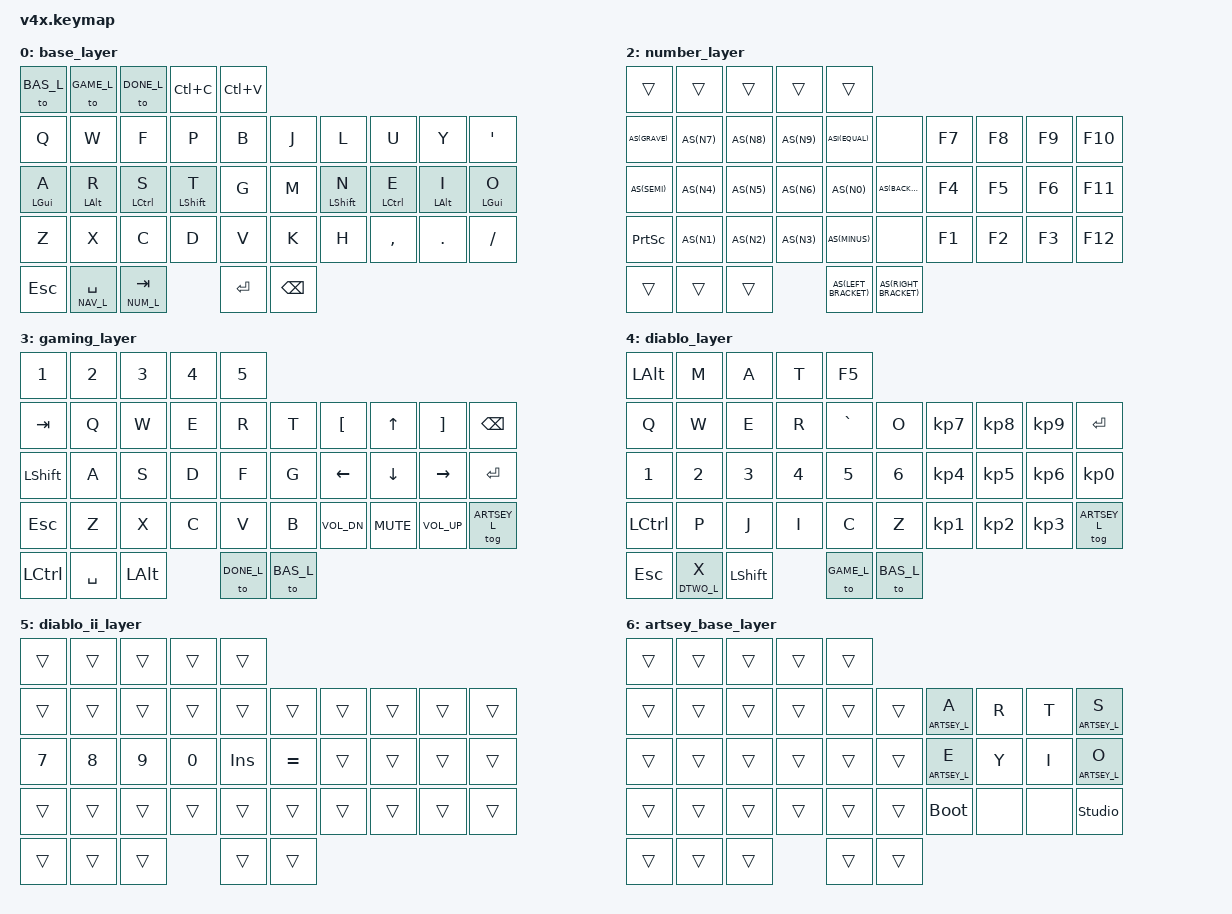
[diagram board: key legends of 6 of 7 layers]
/*
 * Copyright (c) 2024 Rooks
 * 
 * SPDX-License-Identifier: MIT
 */

#include <behaviors.dtsi>
#include <dt-bindings/zmk/keys.h>
#include <dt-bindings/zmk/bt.h>
#include <dt-bindings/zmk/outputs.h>

#define AS(keycode) &as LS(keycode) keycode     // Autoshift Macro
#define ASI(keycode) &as keycode LS(keycode)     // Autoshift Macro inverted
#define BAS_L 0
#define NAV_L 1
#define NUM_L 2
#define GAME_L 3
#define DONE_L 4
#define DTWO_L 5
#define ARTSEY_L 6

#define KEYS_L 5  6  7  8  9   15 16 17 18 19  25 26 27 28 29
#define KEYS_R 10 11 12 13 14  20 21 22 23 24  30 31 32 33 34

#define THUMBS 35 36 37 38 39

// Using layer taps on thumbs, having quick tap as well helps w/ repeating space/backspace
&lt { quick_tap_ms = <200>; };

#define BT(n) BT_SEL n

/ {
    behaviors {
        hml: hrm_left {
            compatible = "zmk,behavior-hold-tap";
            #binding-cells = <2>;
            flavor = "balanced";
            tapping-term-ms = <200>;
            quick-tap-ms = <150>;
            bindings = <&kp>, <&kp>;
            hold-trigger-key-positions = <KEYS_R THUMBS>;
            hold-trigger-on-release;
        };
        hmr: hrm_right {
            compatible = "zmk,behavior-hold-tap";
            #binding-cells = <2>;
            flavor = "balanced";
            tapping-term-ms = <200>;
            quick-tap-ms = <150>;
            bindings = <&kp>, <&kp>;
            hold-trigger-key-positions = <KEYS_L THUMBS>;
            hold-trigger-on-release;
        };
        as: auto_shift {
            compatible = "zmk,behavior-hold-tap";
            #binding-cells = <2>;
            tapping_term_ms = <200>;
            quick_tap_ms = <100>;
            flavor = "tap-preferred";
            bindings = <&kp>, <&kp>;
        };
    };

    keymap {
        compatible = "zmk,keymap";

        base_layer {
            bindings = <
                       &to BAS_L    &to GAME_L &to DONE_L &kp LC(C) &kp LC(V)
                &kp Q         &kp W         &kp F          &kp P           &kp B       &kp J      &kp L          &kp U          &kp Y         &kp QUOT
                &hml LGUI A   &hml LALT R   &hml LCTRL S   &hml LSHFT T    &kp G       &kp M      &hmr LSHFT N   &hmr LCTRL E   &hmr LALT I   &hmr LGUI O   
                &kp Z         &kp X         &kp C          &kp D           &kp V       &kp K      &kp H          &kp COMMA      &kp DOT       &kp FSLH
                &kp ESC        &lt NAV_L SPACE &lt NUM_L TAB        &kp RET    &kp BKSP
                >;
        };
        navigate_layer {
            bindings = <
                &trans &bt BT(0) &bt BT(1) &kp C_VOL_DN &kp C_VOL_UP
                &none &none &none &none &kp HOME     &kp PG_UP    &kp C_MUTE  &kp C_VOL_DN &kp C_VOL_UP &none
                &kp LEFT       &kp DOWN       &kp UP       &kp RIGHT       &out OUT_USB &out OUT_BLE &kp LSHFT &kp LCTRL    &kp LALT     &kp LGUI
                &none &none &none &none &kp END      &kp PG_DN    &caps_word &bt BT(0)    &bt BT(1)    &bt BT(2)
                                              &trans       &trans          &none &none &none
                >;
        };

        number_layer {
            bindings = <
                &trans &trans &trans &trans &trans
                AS(GRAVE) AS(N7) AS(N8) AS(N9) ASI(EQUAL) &none &kp F7 &kp F8 &kp F9 &kp F10
                AS(SEMI)  AS(N4) AS(N5) AS(N6) AS(N0)     AS(BACKSLASH) &kp F4 &kp F5 &kp F6 &kp F11
                &kp PSCRN AS(N1) AS(N2) AS(N3) AS(MINUS)  &none &kp F1 &kp F2 &kp F3 &kp F12
                    &trans &trans &trans AS(LEFT_BRACKET) AS(RIGHT_BRACKET)
                >;
        };

        gaming_layer {
            bindings = <
                &kp N1 &kp N2 &kp N3 &kp N4 &kp N5
                &kp TAB    &kp Q &kp W &kp E &kp R &kp T &kp LEFT_BRACKET &kp UP   &kp RIGHT_BRACKET &kp BACKSPACE
                &kp LSHIFT &kp A &kp S &kp D &kp F &kp G &kp LEFT         &kp DOWN &kp RIGHT         &kp RETURN
                &kp ESC    &kp Z &kp X &kp C &kp V &kp B &kp C_VOL_DN &kp C_MUTE &kp C_VOL_UP &tog ARTSEY_L 
                &kp LCTRL &kp SPACE &kp LALT &to DONE_L &to BAS_L
                >;
        };

        diablo_layer {
            bindings = <
                &kp LALT &kp M &kp A &kp T &kp F5
                &kp Q &kp W &kp E &kp R &kp GRAVE &kp O &kp KP_N7 &kp KP_N8 &kp KP_N9 &kp RETURN
                &kp N1 &kp N2 &kp N3 &kp N4 &kp N5 &kp N6 &kp KP_N4 &kp KP_N5 &kp KP_N6 &kp KP_N0
                &kp LCTRL &kp P &kp J &kp I &kp C &kp Z &kp KP_N1 &kp KP_N2 &kp KP_N3 &tog ARTSEY_L
                &kp ESC &lt DTWO_L X &kp LSHIFT &to GAME_L &to BAS_L
                >;
        };

        diablo_ii_layer {
            bindings = <
                &trans &trans &trans &trans &trans
                &trans &trans &trans &trans &trans &trans &trans &trans &trans &trans
                &kp N7 &kp N8 &kp N9 &kp N0 &kp INS &kp EQUAL &trans &trans &trans &trans
                &trans &trans &trans &trans &trans &trans &trans &trans &trans &trans
                &trans &trans &trans &trans &trans
                >;
        };

        artsey_base_layer {
            bindings = <
                &trans &trans &trans &trans &trans
                &trans &trans &trans &trans &trans &trans &lt ARTSEY_L A &kp R &kp T &lt ARTSEY_L S
                &trans &trans &trans &trans &trans &trans &lt ARTSEY_L E &kp Y &kp I &lt ARTSEY_L O
                &trans &trans &trans &trans &trans &trans &bootloader &none &none &studio_unlock
                &trans &trans &trans &trans &trans
                >;
        };
    };

    combos {
        compatible = "zmk,combos";
        combo_boot { timeout-ms = <50>; key-positions = <5 14 25 34>; bindings = <&bootloader>; };
        combo_del { timeout-ms = <50>; key-positions = <34 39>; bindings = <&kp DEL>; layers = <BAS_L>; };
    };
};

// vim: ft=c
